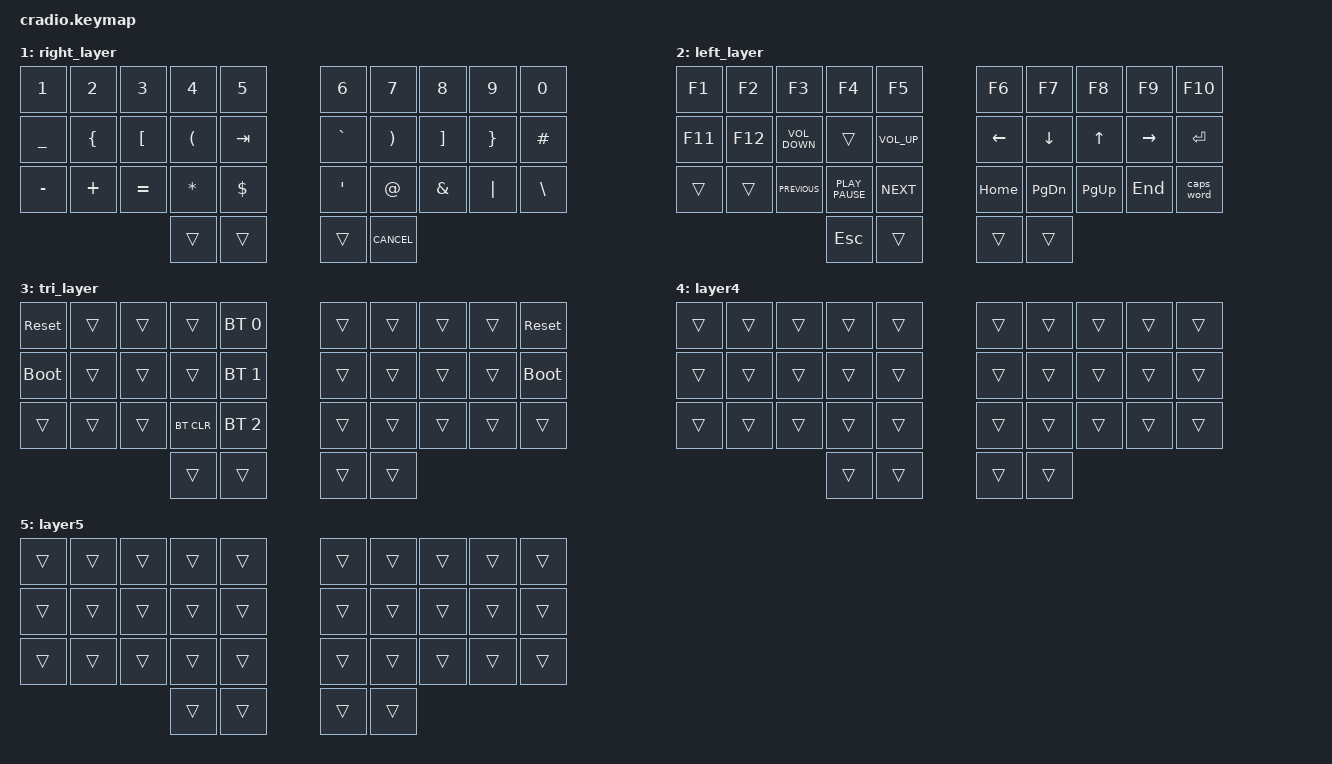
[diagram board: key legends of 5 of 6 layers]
// Copyright (c) 2022 The ZMK Contributors
// SPDX-License-Identifier: MIT

#include <behaviors.dtsi>
#include <dt-bindings/zmk/keys.h>
#include <dt-bindings/zmk/bt.h>

// Home row mods macro
#define HRML(k1,k2,k3,k4) &ht LSHFT k1  &ht LCTRL k2  &ht LALT  k3  &ht LGUI k4
#define HRMR(k1,k2,k3,k4) &ht RGUI k1  &ht LALT k2  &ht RCTRL  k3  &ht RSHFT k4

&caps_word {
    continue-list = <UNDERSCORE MINUS>;
};


/ {
  combos {
    compatible = "zmk,combos";

    combo_enter {
      bindings = <&kp ENTER>;
      key-positions = <26 27>;
      layers=<0>;
      timeout-ms=<50>;
    };
    combo_tab {
      bindings = <&kp TAB>;
      key-positions = <22 23>;
      layers=<0>;
      require-prior-idle-ms=<50>;
    };
    combo_esc {
      bindings = <&kp ESC>;
      key-positions = <2 3>;
      layers=<0>;
      timeout-ms=<50>;
    };
    combo_bkp {
      bindings = <&kp DELETE>;
      key-positions = <6 7>;
      layers=<0>;
      timeout-ms=<50>;
    };
    combo_copy {
      bindings = <&kp C_AC_COPY>;
      key-positions = <21 22>;
      layers=<0>;
      timeout-ms=<50>;
    };
    combo_paste {
      bindings = <&kp C_AC_PASTE>;
      key-positions = <22 23>;
      layers=<0>;
      timeout-ms=<50>;
    };
     combo_cut {
      bindings = <&kp C_AC_CUT>;
      key-positions = <21 23>;
      layers=<0>;
      timeout-ms=<50>;
    };
  };
};

/ {
    behaviors {
        ht: hold_tap {
            compatible = "zmk,behavior-hold-tap";
            #binding-cells = <2>;
            flavor = "tap-preferred";
            tapping-term-ms = <220>;
            quick-tap-ms = <150>;
            require-prior-idle-ms = <100>;
            bindings = <&kp>, <&kp>;
        };
    };

    conditional_layers {
        compatible = "zmk,conditional-layers";
        tri_layer {
            if-layers = <1 2>;
            then-layer = <3>;
        };
    };

    keymap {
        compatible = "zmk,keymap";
        default_layer {
            bindings = <
        //╭──────────┬──────────┬──────────┬──────────┬──────────╮   ╭──────────┬──────────┬──────────┬──────────┬──────────╮
        //│  Q       │  W       │  E       │  R       │  T       │   │  Y       │  U       │  I       │  O       │  P       │
            &kp Q      &kp W      &kp E      &kp R      &kp T          &kp Y      &kp U      &kp I      &kp O      &kp P
        //├──────────┼──────────┼──────────┼──────────┼──────────┤   ├──────────┼──────────┼──────────┼──────────┼──────────┤
        //│  A       │  S       │  D       │  F       │  G       │   │  H       │  J       │  K       │  L       │ ; :      │
            HRML(A,        S,         D,         F)     &kp G          &kp H      HRMR(J,        K,         L,    SEMICOLON)
        //├──────────┼──────────┼──────────┼──────────┼──────────┤   ├──────────┼──────────┼──────────┼──────────┼──────────┤
        //│  Z       │  X       │  C       │  V       │  B       │   │  N       │  M       │ , <      │ . >      │ / ?      │
            &kp Z      &kp X      &kp C      &kp V      &kp B          &kp N      &kp M      &kp COMMA  &kp DOT    &kp FSLH
        //╰──────────┴──────────┴──────────┼──────────┼──────────┤   ├──────────┼──────────┼──────────┴──────────┴──────────╯
                                            &kp SPACE   &mo 1         &mo 2      &kp BSPC
        //                                 ╰──────────┴──────────╯   ╰──────────┴──────────╯
            >;
        };

        right_layer {
            bindings = <
        //╭──────────┬──────────┬──────────┬──────────┬──────────╮   ╭──────────┬──────────┬──────────┬──────────┬──────────╮
        //│ INSERT   │  1       │  2       │  3       │          │   │ HOME     │ PAGE DN  │ PAGE UP  │ END      │  :       │
            &kp N1    &kp N2     &kp N3     &kp N4     &kp N5         &kp N6   &kp N7  &kp N8  &kp N9    &kp N0
        //├──────────┼──────────┼──────────┼──────────┼──────────┤   ├──────────┼──────────┼──────────┼──────────┼──────────┤
        //│ DELETE   │  4       │  5       │  6       │          │   │ LEFT     │ DOWN     │ UP       │ RIGHT    │  ;       │
          &kp UNDERSCORE &kp LBRC  &kp LBKT  &kp LPAR   &kp TAB       &kp GRAVE  &kp RPAR   &kp RBKT   &kp RBRC   &kp HASH 
        //├──────────┼──────────┼──────────┼──────────┼──────────┤   ├──────────┼──────────┼──────────┼──────────┼──────────┤
        //│ CAPS     │  7       │  8       │  9       │  0       │   │          │          │          │          │          │
           &kp MINUS &kp PLUS   &kp EQUAL  &kp ASTRK     &kp DOLLAR   &kp APOS  &kp AT     &kp AMPERSAND &kp PIPE &kp BACKSLASH
        //╰──────────┴──────────┴──────────┼──────────┼──────────┤   ├──────────┼──────────┼──────────┴──────────┴──────────╯
                                             &trans     &trans        &trans     &kp K_CANCEL
        //                                 ╰──────────┴──────────╯   ╰──────────┴──────────╯
            >;
        };

        left_layer {
            bindings = <
        //╭──────────┬──────────┬──────────┬──────────┬──────────╮   ╭──────────┬──────────┬──────────┬──────────┬──────────╮
        //│          │  [       │  {       │  }       │          │   │  ^       │  (       │  )       │  ]       │  ~       │
            &kp F1  &kp F2 &kp F3 &kp F4 &kp F5 &kp F6 &kp F7 &kp F8 &kp F9 &kp F10
        //├──────────┼──────────┼──────────┼──────────┼──────────┤   ├──────────┼──────────┼──────────┼──────────┼──────────┤
        //│  !       │  @       │  #       │  $       │  %       │   │  *       │  -       │  =       │  \       │  `       │ 
           &kp F11 &kp F12 &kp K_VOLUME_DOWN &trans &kp K_VOLUME_UP  &kp LEFT   &kp DOWN   &kp UP      &kp RIGHT   &kp ENTER
        //├──────────┼──────────┼──────────┼──────────┼──────────┤   ├──────────┼──────────┼──────────┼──────────┼──────────┤
        //│          │          │          │          │          │   │  &       │  _       │  +       │  │       │          │
         //&trans   &trans   &kp K_PREVIOUS &kp K_PLAY_PAUSE &kp K_NEXT &kp HOME &kp PG_DOWN &kp PG_UP &kp END &caps_word

         &trans   &trans   &kp K_PREVIOUS &kp K_PLAY_PAUSE &kp K_NEXT &kp HOME &kp PAGE_DOWN &kp PAGE_UP  &kp END &caps_word
         //&trans   &trans   &trans &trans &trans &kp HOME &kp PG_DOWN &kp PG_UP &kp END &caps_word

        //╰──────────┴──────────┴──────────┼──────────┼──────────┤   ├──────────┼──────────┼──────────┴──────────┴──────────╯
                                             &kp ESC     &trans         &trans     &trans
        //                                 ╰──────────┴──────────╯   ╰──────────┴──────────╯
            >;
        };

        tri_layer {
            bindings = <
        //╭──────────┬──────────┬──────────┬──────────┬──────────╮   ╭──────────┬──────────┬──────────┬──────────┬──────────╮
        //│ RESET    │          │          │          │PROFILE 0 │   │          │          │          │          │  RESET   │
           &sys_reset  &trans     &trans     &trans    &bt BT_SEL 0    &trans     &trans     &trans     &trans    &sys_reset
        //├──────────┼──────────┼──────────┼──────────┼──────────┤   ├──────────┼──────────┼──────────┼──────────┼──────────┤
        //│BOOTLOADER│          │          │          │PROFILE 1 │   │          │          │          │          │BOOTLOADER│
          &bootloader  &trans     &trans     &trans    &bt BT_SEL 1    &trans     &trans     &trans     &trans    &bootloader
        //├──────────┼──────────┼──────────┼──────────┼──────────┤   ├──────────┼──────────┼──────────┼──────────┼──────────┤
        //│          │          │          │ CLEAR BT │PROFILE 2 │   │          │          │          │          │          │
            &trans     &trans     &trans    &bt BT_CLR &bt BT_SEL 2    &trans     &trans     &trans     &trans     &trans
        //╰──────────┴──────────┴──────────┼──────────┼──────────┤   ├──────────┼──────────┼──────────┴──────────┴──────────╯
                                             &trans     &trans         &trans     &trans
        //                                 ╰──────────┴──────────╯   ╰──────────┴──────────╯
            >;
        };

        layer4 {
          bindings = <
            &trans     &trans     &trans     &trans     &trans     &trans     &trans     &trans     &trans     &trans

            &trans     &trans     &trans     &trans     &trans     &trans     &trans     &trans     &trans     &trans

            &trans     &trans     &trans     &trans     &trans     &trans     &trans     &trans     &trans     &trans
                                            &trans     &trans     &trans     &trans
          >;
        };
        layer5 {
          bindings = <
            &trans     &trans     &trans     &trans     &trans     &trans     &trans     &trans     &trans     &trans

            &trans     &trans     &trans     &trans     &trans     &trans     &trans     &trans     &trans     &trans

            &trans     &trans     &trans     &trans     &trans     &trans     &trans     &trans     &trans     &trans
                                            &trans     &trans     &trans     &trans
          >;
        };
    };
};
